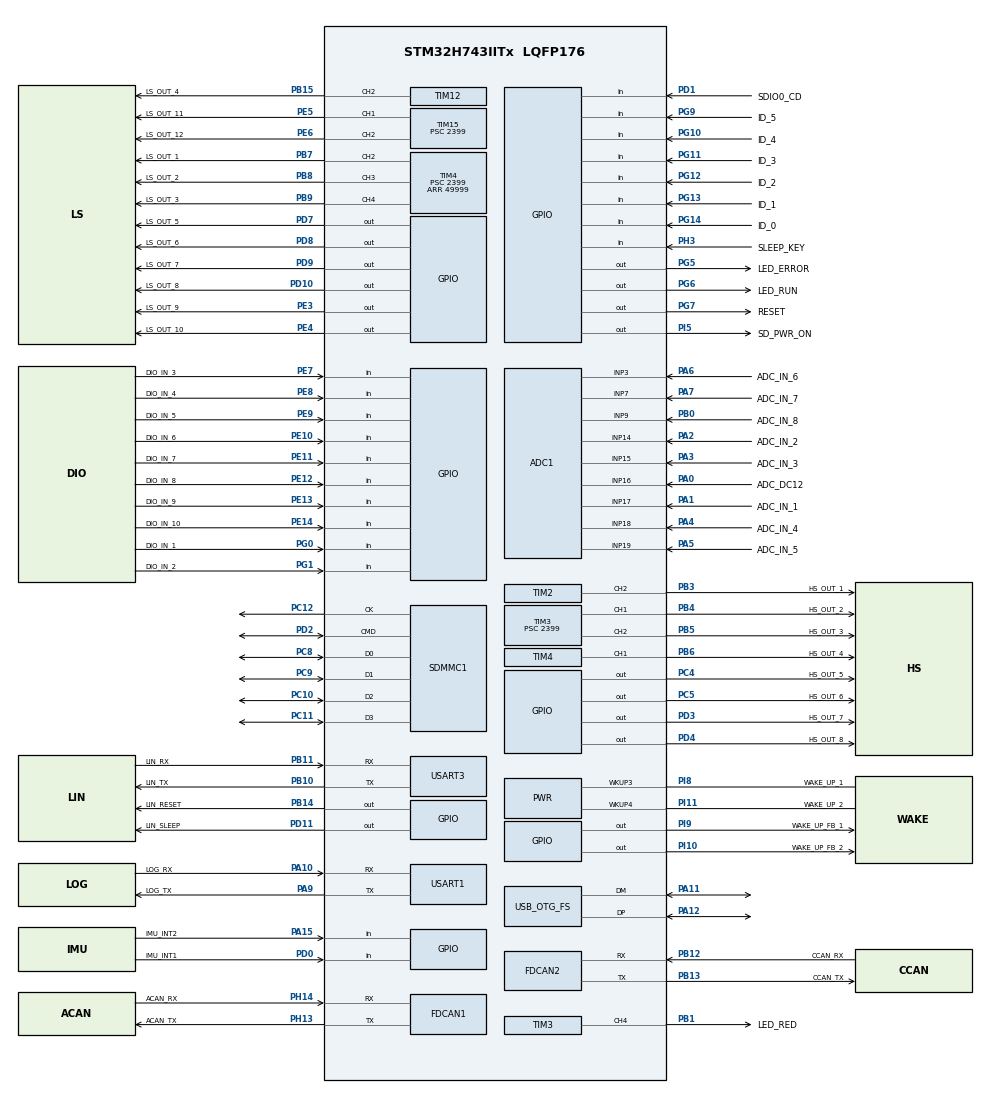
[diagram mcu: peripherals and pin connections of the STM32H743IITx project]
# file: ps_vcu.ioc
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ADC1.Channel-10\#ChannelRegularConversion=ADC_CHANNEL_9
ADC1.Channel-2\#ChannelRegularConversion=ADC_CHANNEL_16
ADC1.Channel-3\#ChannelRegularConversion=ADC_CHANNEL_17
ADC1.Channel-4\#ChannelRegularConversion=ADC_CHANNEL_14
ADC1.Channel-5\#ChannelRegularConversion=ADC_CHANNEL_15
ADC1.Channel-6\#ChannelRegularConversion=ADC_CHANNEL_18
ADC1.Channel-7\#ChannelRegularConversion=ADC_CHANNEL_19
ADC1.Channel-8\#ChannelRegularConversion=ADC_CHANNEL_3
ADC1.Channel-9\#ChannelRegularConversion=ADC_CHANNEL_7
ADC1.ContinuousConvMode=ENABLE
ADC1.ConversionDataManagement=ADC_CONVERSIONDATA_DMA_CIRCULAR
ADC1.NbrOfConversion=9
ADC1.NbrOfConversionFlag=1
ADC1.OffsetNumber-10\#ChannelRegularConversion=ADC_OFFSET_NONE
ADC1.OffsetNumber-2\#ChannelRegularConversion=ADC_OFFSET_NONE
ADC1.OffsetNumber-3\#ChannelRegularConversion=ADC_OFFSET_NONE
ADC1.OffsetNumber-4\#ChannelRegularConversion=ADC_OFFSET_NONE
ADC1.OffsetNumber-5\#ChannelRegularConversion=ADC_OFFSET_NONE
ADC1.OffsetNumber-6\#ChannelRegularConversion=ADC_OFFSET_NONE
ADC1.OffsetNumber-7\#ChannelRegularConversion=ADC_OFFSET_NONE
ADC1.OffsetNumber-8\#ChannelRegularConversion=ADC_OFFSET_NONE
ADC1.OffsetNumber-9\#ChannelRegularConversion=ADC_OFFSET_NONE
ADC1.OffsetSignedSaturation-10\#ChannelRegularConversion=DISABLE
ADC1.OffsetSignedSaturation-2\#ChannelRegularConversion=DISABLE
ADC1.OffsetSignedSaturation-3\#ChannelRegularConversion=DISABLE
ADC1.OffsetSignedSaturation-4\#ChannelRegularConversion=DISABLE
ADC1.OffsetSignedSaturation-5\#ChannelRegularConversion=DISABLE
ADC1.OffsetSignedSaturation-6\#ChannelRegularConversion=DISABLE
ADC1.OffsetSignedSaturation-7\#ChannelRegularConversion=DISABLE
ADC1.OffsetSignedSaturation-8\#ChannelRegularConversion=DISABLE
ADC1.OffsetSignedSaturation-9\#ChannelRegularConversion=DISABLE
ADC1.Overrun=ADC_OVR_DATA_OVERWRITTEN
ADC1.Rank-10\#ChannelRegularConversion=9
ADC1.Rank-2\#ChannelRegularConversion=1
ADC1.Rank-3\#ChannelRegularConversion=2
ADC1.Rank-4\#ChannelRegularConversion=3
ADC1.Rank-5\#ChannelRegularConversion=4
ADC1.Rank-6\#ChannelRegularConversion=5
ADC1.Rank-7\#ChannelRegularConversion=6
ADC1.Rank-8\#ChannelRegularConversion=7
ADC1.Rank-9\#ChannelRegularConversion=8
ADC1.SamplingTime-10\#ChannelRegularConversion=ADC_SAMPLETIME_810CYCLES_5
ADC1.SamplingTime-2\#ChannelRegularConversion=ADC_SAMPLETIME_810CYCLES_5
ADC1.SamplingTime-3\#ChannelRegularConversion=ADC_SAMPLETIME_810CYCLES_5
ADC1.SamplingTime-4\#ChannelRegularConversion=ADC_SAMPLETIME_810CYCLES_5
ADC1.SamplingTime-5\#ChannelRegularConversion=ADC_SAMPLETIME_810CYCLES_5
ADC1.SamplingTime-6\#ChannelRegularConversion=ADC_SAMPLETIME_810CYCLES_5
ADC1.SamplingTime-7\#ChannelRegularConversion=ADC_SAMPLETIME_810CYCLES_5
ADC1.SamplingTime-8\#ChannelRegularConversion=ADC_SAMPLETIME_810CYCLES_5
ADC1.SamplingTime-9\#ChannelRegularConversion=ADC_SAMPLETIME_810CYCLES_5
ADC1.master=1
ADC3.Channel-0\#ChannelRegularConversion=ADC_CHANNEL_TEMPSENSOR
ADC3.ContinuousConvMode=ENABLE
ADC3.ConversionDataManagement=ADC_CONVERSIONDATA_DMA_CIRCULAR
ADC3.NbrOfConversionFlag=1
ADC3.OffsetNumber-0\#ChannelRegularConversion=ADC_OFFSET_NONE
ADC3.OffsetSignedSaturation-0\#ChannelRegularConversion=DISABLE
ADC3.Overrun=ADC_OVR_DATA_OVERWRITTEN
ADC3.Rank-0\#ChannelRegularConversion=1
ADC3.SamplingTime-0\#ChannelRegularConversion=ADC_SAMPLETIME_810CYCLES_5
CORTEX_M7.AccessPermission-Cortex_Memory_Protection_Unit_Region0_Settings=MPU_REGION_FULL_ACCESS
CORTEX_M7.AccessPermission-Cortex_Memory_Protection_Unit_Region1_Settings=MPU_REGION_FULL_ACCESS
CORTEX_M7.AccessPermission-Cortex_Memory_Protection_Unit_Region2_Settings=MPU_REGION_FULL_ACCESS
CORTEX_M7.AccessPermission-Cortex_Memory_Protection_Unit_Region3_Settings=MPU_REGION_FULL_ACCESS
CORTEX_M7.BaseAddress-Cortex_Memory_Protection_Unit_Region0_Settings=0x20000000
CORTEX_M7.BaseAddress-Cortex_Memory_Protection_Unit_Region1_Settings=0x24000000
CORTEX_M7.BaseAddress-Cortex_Memory_Protection_Unit_Region2_Settings=0x30000000
CORTEX_M7.BaseAddress-Cortex_Memory_Protection_Unit_Region3_Settings=0x38000000
CORTEX_M7.CPU_DCache=Enabled
CORTEX_M7.CPU_ICache=Enabled
CORTEX_M7.DisableExec-Cortex_Memory_Protection_Unit_Region0_Settings=MPU_INSTRUCTION_ACCESS_ENABLE
CORTEX_M7.DisableExec-Cortex_Memory_Protection_Unit_Region1_Settings=MPU_INSTRUCTION_ACCESS_ENABLE
CORTEX_M7.Enable-Cortex_Memory_Protection_Unit_Region0_Settings=MPU_REGION_ENABLE
CORTEX_M7.Enable-Cortex_Memory_Protection_Unit_Region1_Settings=MPU_REGION_ENABLE
CORTEX_M7.Enable-Cortex_Memory_Protection_Unit_Region2_Settings=MPU_REGION_ENABLE
CORTEX_M7.Enable-Cortex_Memory_Protection_Unit_Region3_Settings=MPU_REGION_ENABLE
CORTEX_M7.Enable-Cortex_Memory_Protection_Unit_Region4_Settings=__NULL
CORTEX_M7.IsBufferable-Cortex_Memory_Protection_Unit_Region0_Settings=MPU_ACCESS_BUFFERABLE
CORTEX_M7.IsBufferable-Cortex_Memory_Protection_Unit_Region1_Settings=MPU_ACCESS_NOT_BUFFERABLE
CORTEX_M7.IsBufferable-Cortex_Memory_Protection_Unit_Region2_Settings=MPU_ACCESS_BUFFERABLE
CORTEX_M7.IsBufferable-Cortex_Memory_Protection_Unit_Region3_Settings=MPU_ACCESS_BUFFERABLE
CORTEX_M7.IsCacheable-Cortex_Memory_Protection_Unit_Region0_Settings=MPU_ACCESS_CACHEABLE
CORTEX_M7.IsCacheable-Cortex_Memory_Protection_Unit_Region1_Settings=MPU_ACCESS_CACHEABLE
CORTEX_M7.IsCacheable-Cortex_Memory_Protection_Unit_Region2_Settings=MPU_ACCESS_CACHEABLE
CORTEX_M7.IsCacheable-Cortex_Memory_Protection_Unit_Region3_Settings=MPU_ACCESS_CACHEABLE
CORTEX_M7.IsShareable-Cortex_Memory_Protection_Unit_Region1_Settings=MPU_ACCESS_SHAREABLE
CORTEX_M7.MPU_Control=MPU_HFNMI_PRIVDEF
CORTEX_M7.Size-Cortex_Memory_Protection_Unit_Region0_Settings=MPU_REGION_SIZE_128KB
CORTEX_M7.Size-Cortex_Memory_Protection_Unit_Region1_Settings=MPU_REGION_SIZE_512KB
CORTEX_M7.Size-Cortex_Memory_Protection_Unit_Region2_Settings=MPU_REGION_SIZE_512KB
CORTEX_M7.Size-Cortex_Memory_Protection_Unit_Region3_Settings=MPU_REGION_SIZE_64KB
CORTEX_M7.TypeExtField-Cortex_Memory_Protection_Unit_Region0_Settings=MPU_TEX_LEVEL0
FATFS.BSP.number=1
FATFS._CODE_PAGE=437
FATFS._USE_LABEL=1
FATFS._USE_LFN=2
FATFS0.BSP.STBoard=false
FATFS0.BSP.api=Unknown
FATFS0.BSP.instance=PD1
FATFS0.BSP.ip=GPIO
FATFS0.BSP.mode=Input
FATFS0.BSP.name=Detect_SDIO
FATFS0.BSP.solution=PD1
FDCAN1.CalculateBaudRateNominal=500000
FDCAN1.CalculateTimeBitNominal=2000
FDCAN1.CalculateTimeQuantumNominal=50.0
FDCAN1.DataPrescaler=6
FDCAN1.DataSyncJumpWidth=8
FDCAN1.DataTimeSeg1=31
FDCAN1.DataTimeSeg2=8
FDCAN1.Mode=FDCAN_MODE_NORMAL
FDCAN1.NominalPrescaler=6
FDCAN1.NominalSyncJumpWidth=8
FDCAN1.NominalTimeSeg1=31
FDCAN1.NominalTimeSeg2=8
FDCAN1.ProtocolException=ENABLE
FDCAN1.RxFifo0ElmtsNbr=32
FDCAN1.StdFiltersNbr=128
FDCAN1.TxFifoQueueElmtsNbr=32
FDCAN2.CalculateBaudRateNominal=500000
FDCAN2.CalculateTimeBitNominal=2000
FDCAN2.CalculateTimeQuantumNominal=50.0
FDCAN2.DataPrescaler=6
FDCAN2.DataSyncJumpWidth=8
FDCAN2.DataTimeSeg1=31
FDCAN2.DataTimeSeg2=8
FDCAN2.MessageRAMOffset=0x406
FDCAN2.Mode=FDCAN_MODE_NORMAL
FDCAN2.NominalPrescaler=6
FDCAN2.NominalSyncJumpWidth=8
FDCAN2.NominalTimeSeg1=31
FDCAN2.NominalTimeSeg2=8
FDCAN2.ProtocolException=ENABLE
FDCAN2.RxFifo1ElmtsNbr=32
FDCAN2.StdFiltersNbr=1
FDCAN2.TxFifoQueueElmtsNbr=32
FREERTOS.HEAP_NUMBER=1
FREERTOS.Tasks01=idle_task,8,512,IdleTask,Default,NULL,Dynamic,NULL,NULL;can_recv_task,24,512,CanRecvTask,Default,NULL,Dynamic,NULL,NULL;can_send_task,24,512,CanSendTask,Default,NULL,Dynamic,NULL,NULL
FREERTOS.configTIMER_TASK_PRIORITY=2
FREERTOS.configTIMER_TASK_STACK_DEPTH=256
Mcu.Family=STM32H7
Mcu.Name=STM32H743IITx
Mcu.Package=LQFP176
NVIC.FDCAN1_IT0_IRQn=true\:5\:0\:false\:false\:true\:true\:true\:true\:true
NVIC.FDCAN2_IT0_IRQn=true\:5\:0\:false\:false\:true\:true\:true\:true\:true
NVIC.OTG_FS_IRQn=true\:5\:0\:false\:false\:true\:true\:true\:true\:true
NVIC.PriorityGroup=NVIC_PRIORITYGROUP_4
NVIC.SDMMC1_IRQn=true\:5\:0\:false\:false\:true\:true\:true\:true\:true
NVIC.TIM7_IRQn=true\:15\:0\:false\:false\:true\:false\:false\:true\:true
NVIC.TIM8_UP_TIM13_IRQn=true\:6\:0\:true\:false\:true\:true\:true\:true\:true
NVIC.TimeBase=TIM7_IRQn
NVIC.TimeBaseIP=TIM7
NVIC.USART1_IRQn=true\:8\:0\:true\:false\:true\:true\:true\:true\:true
NVIC.USART3_IRQn=true\:5\:0\:false\:false\:true\:true\:true\:true\:true
PA0.GPIO_Label=ADC_DC12
PA0.Mode=IN16-Single-Ended
PA0.Signal=ADC1_INP16
PA1.GPIO_Label=ADC_IN_1
PA1.Mode=IN17-Single-Ended
PA1.Signal=ADC1_INP17
PA10.GPIO_Label=LOG_RX
PA10.Mode=Asynchronous
PA10.Signal=USART1_RX
PA11.Mode=Device_Only
PA11.Signal=USB_OTG_FS_DM
PA12.Mode=Device_Only
PA12.Signal=USB_OTG_FS_DP
PA13\ (JTMS/SWDIO).Mode=Serial_Wire
PA13\ (JTMS/SWDIO).Signal=DEBUG_JTMS-SWDIO
PA14\ (JTCK/SWCLK).Mode=Serial_Wire
PA14\ (JTCK/SWCLK).Signal=DEBUG_JTCK-SWCLK
PA15\ (JTDI).GPIO_Label=IMU_INT2
PA15\ (JTDI).Signal=GPIO_Input
PA2.GPIO_Label=ADC_IN_2
PA2.Signal=ADCx_INP14
PA3.GPIO_Label=ADC_IN_3
PA3.Signal=ADCx_INP15
PA4.GPIO_Label=ADC_IN_4
PA4.Signal=ADCx_INP18
PA5.GPIO_Label=ADC_IN_5
PA5.Signal=ADCx_INP19
PA6.GPIO_Label=ADC_IN_6
PA6.Signal=ADCx_INP3
PA7.GPIO_Label=ADC_IN_7
PA7.Signal=ADCx_INP7
PA9.GPIO_Label=LOG_TX
PA9.Mode=Asynchronous
PA9.Signal=USART1_TX
PB0.GPIO_Label=ADC_IN_8
PB0.Signal=ADCx_INP9
PB1.GPIO_Label=LED_RED
PB1.GPIO_PuPd=GPIO_PULLUP
PB1.Signal=S_TIM3_CH4
PB10.GPIO_Label=LIN_TX
PB10.Mode=LIN
PB10.Signal=USART3_TX
PB11.GPIO_Label=LIN_RX
PB11.Mode=LIN
PB11.Signal=USART3_RX
PB12.GPIO_Label=CCAN_RX
PB12.GPIO_PuPd=GPIO_NOPULL
PB12.GPIO_Speed=GPIO_SPEED_FREQ_VERY_HIGH
PB12.Mode=FDCAN_Activate
PB12.Signal=FDCAN2_RX
PB13.GPIO_Label=CCAN_TX
PB13.GPIO_PuPd=GPIO_NOPULL
PB13.GPIO_Speed=GPIO_SPEED_FREQ_VERY_HIGH
PB13.Mode=FDCAN_Activate
PB13.Signal=FDCAN2_TX
PB14.GPIO_Label=LIN_RESET
PB14.GPIO_PuPd=GPIO_PULLUP
PB14.Signal=GPIO_Output
PB15.GPIO_Label=LS_OUT_4
PB15.GPIO_PuPd=GPIO_PULLUP
PB15.Signal=S_TIM12_CH2
PB3\ (JTDO/TRACESWO).GPIO_Label=HS_OUT_1
PB3\ (JTDO/TRACESWO).GPIO_PuPd=GPIO_PULLDOWN
PB3\ (JTDO/TRACESWO).Signal=S_TIM2_CH2
PB4\ (NJTRST).GPIO_Label=HS_OUT_2
PB4\ (NJTRST).GPIO_PuPd=GPIO_PULLDOWN
PB4\ (NJTRST).Signal=S_TIM3_CH1
PB5.GPIO_Label=HS_OUT_3
PB5.GPIO_PuPd=GPIO_PULLDOWN
PB5.Signal=S_TIM3_CH2
PB6.GPIO_Label=HS_OUT_4
PB6.GPIO_PuPd=GPIO_PULLDOWN
PB6.Signal=S_TIM4_CH1
PB7.GPIO_Label=LS_OUT_1
PB7.GPIO_PuPd=GPIO_PULLUP
PB7.Signal=S_TIM4_CH2
PB8.GPIO_Label=LS_OUT_2
PB8.GPIO_PuPd=GPIO_PULLUP
PB8.Signal=S_TIM4_CH3
PB9.GPIO_Label=LS_OUT_3
PB9.GPIO_PuPd=GPIO_PULLUP
PB9.Signal=S_TIM4_CH4
PC10.Mode=SD_4_bits_Wide_bus
PC10.Signal=SDMMC1_D2
PC11.Mode=SD_4_bits_Wide_bus
PC11.Signal=SDMMC1_D3
PC12.Mode=SD_4_bits_Wide_bus
PC12.Signal=SDMMC1_CK
PC14-OSC32_IN\ (OSC32_IN).Mode=LSE-External-Oscillator
PC14-OSC32_IN\ (OSC32_IN).Signal=RCC_OSC32_IN
PC15-OSC32_OUT\ (OSC32_OUT).Mode=LSE-External-Oscillator
PC15-OSC32_OUT\ (OSC32_OUT).Signal=RCC_OSC32_OUT
PC4.GPIO_Label=HS_OUT_5
PC4.GPIO_PuPd=GPIO_PULLDOWN
PC4.Signal=GPIO_Output
PC5.GPIO_Label=HS_OUT_6
PC5.GPIO_PuPd=GPIO_PULLDOWN
PC5.Signal=GPIO_Output
PC8.Mode=SD_4_bits_Wide_bus
PC8.Signal=SDMMC1_D0
PC9.Mode=SD_4_bits_Wide_bus
PC9.Signal=SDMMC1_D1
PD0.GPIO_Label=IMU_INT1
PD0.Signal=GPIO_Input
PD1.GPIO_Label=SDIO0_CD
PD1.Signal=GPIO_Input
PD10.GPIO_Label=LS_OUT_8
PD10.GPIO_PuPd=GPIO_PULLUP
PD10.PinState=GPIO_PIN_SET
PD10.Signal=GPIO_Output
PD11.GPIO_Label=LIN_SLEEP
PD11.GPIO_PuPd=GPIO_PULLDOWN
PD11.Signal=GPIO_Output
PD2.Mode=SD_4_bits_Wide_bus
PD2.Signal=SDMMC1_CMD
PD3.GPIO_Label=HS_OUT_7
PD3.GPIO_PuPd=GPIO_PULLDOWN
PD3.Signal=GPIO_Output
PD4.GPIO_Label=HS_OUT_8
PD4.GPIO_PuPd=GPIO_PULLDOWN
PD4.Signal=GPIO_Output
PD7.GPIO_Label=LS_OUT_5
PD7.GPIO_PuPd=GPIO_PULLUP
PD7.PinState=GPIO_PIN_SET
PD7.Signal=GPIO_Output
PD8.GPIO_Label=LS_OUT_6
PD8.GPIO_PuPd=GPIO_PULLUP
PD8.PinState=GPIO_PIN_SET
PD8.Signal=GPIO_Output
PD9.GPIO_Label=LS_OUT_7
PD9.GPIO_PuPd=GPIO_PULLUP
PD9.PinState=GPIO_PIN_SET
PD9.Signal=GPIO_Output
PE10.GPIO_Label=DIO_IN_6
PE10.Signal=GPIO_Input
PE11.GPIO_Label=DIO_IN_7
PE11.GPIO_PuPd=GPIO_PULLUP
PE11.Signal=GPIO_Input
PE12.GPIO_Label=DIO_IN_8
PE12.GPIO_PuPd=GPIO_PULLUP
PE12.Signal=GPIO_Input
PE13.GPIO_Label=DIO_IN_9
PE13.GPIO_PuPd=GPIO_PULLUP
PE13.Signal=GPIO_Input
PE14.GPIO_Label=DIO_IN_10
PE14.GPIO_PuPd=GPIO_PULLUP
PE14.Signal=GPIO_Input
PE3.GPIO_Label=LS_OUT_9
PE3.GPIO_PuPd=GPIO_PULLUP
PE3.PinState=GPIO_PIN_SET
PE3.Signal=GPIO_Output
PE4.GPIO_Label=LS_OUT_10
PE4.GPIO_PuPd=GPIO_PULLUP
PE4.PinState=GPIO_PIN_SET
PE4.Signal=GPIO_Output
PE5.GPIO_Label=LS_OUT_11
PE5.GPIO_PuPd=GPIO_PULLUP
PE5.Signal=S_TIM15_CH1
PE6.GPIO_Label=LS_OUT_12
PE6.GPIO_PuPd=GPIO_PULLUP
PE6.Signal=S_TIM15_CH2
PE7.GPIO_Label=DIO_IN_3
PE7.GPIO_PuPd=GPIO_PULLUP
PE7.Signal=GPIO_Input
PE8.GPIO_Label=DIO_IN_4
PE8.GPIO_PuPd=GPIO_PULLUP
PE8.Signal=GPIO_Input
PE9.GPIO_Label=DIO_IN_5
PE9.GPIO_PuPd=GPIO_PULLUP
PE9.Signal=GPIO_Input
PG0.GPIO_Label=DIO_IN_1
PG0.GPIO_PuPd=GPIO_PULLUP
PG0.Signal=GPIO_Input
PG1.GPIO_Label=DIO_IN_2
PG1.GPIO_PuPd=GPIO_PULLUP
PG1.Signal=GPIO_Input
PG10.GPIO_Label=ID_4
PG10.Signal=GPIO_Input
PG11.GPIO_Label=ID_3
PG11.Signal=GPIO_Input
PG12.GPIO_Label=ID_2
PG12.Signal=GPIO_Input
PG13.GPIO_Label=ID_1
PG13.Signal=GPIO_Input
PG14.GPIO_Label=ID_0
PG14.Signal=GPIO_Input
PG5.GPIO_Label=LED_ERROR
PG5.GPIO_ModeDefaultOutputPP=GPIO_MODE_OUTPUT_PP
PG5.GPIO_PuPd=GPIO_PULLUP
PG5.PinState=GPIO_PIN_SET
PG5.Signal=GPIO_Output
PG6.GPIO_Label=LED_RUN
PG6.GPIO_PuPd=GPIO_PULLUP
PG6.PinState=GPIO_PIN_SET
PG6.Signal=GPIO_Output
PG7.GPIO_Label=RESET
PG7.GPIO_PuPd=GPIO_PULLUP
PG7.PinState=GPIO_PIN_SET
PG7.Signal=GPIO_Output
PG9.GPIO_Label=ID_5
PG9.Signal=GPIO_Input
PH0-OSC_IN\ (PH0).Mode=HSE-External-Oscillator
PH0-OSC_IN\ (PH0).Signal=RCC_OSC_IN
PH1-OSC_OUT\ (PH1).Mode=HSE-External-Oscillator
PH1-OSC_OUT\ (PH1).Signal=RCC_OSC_OUT
PH13.GPIO_Label=ACAN_TX
PH13.GPIO_PuPd=GPIO_NOPULL
PH13.GPIO_Speed=GPIO_SPEED_FREQ_VERY_HIGH
PH13.Mode=FDCAN_Activate
PH13.Signal=FDCAN1_TX
PH14.GPIO_Label=ACAN_RX
PH14.GPIO_PuPd=GPIO_NOPULL
PH14.GPIO_Speed=GPIO_SPEED_FREQ_VERY_HIGH
PH14.Mode=FDCAN_Activate
PH14.Signal=FDCAN1_RX
PH3.GPIO_Label=SLEEP_KEY
PH3.GPIO_PuPd=GPIO_PULLUP
PH3.Signal=GPIO_Input
PI10.GPIO_Label=WAKE_UP_FB_2
PI10.GPIO_PuPd=GPIO_PULLDOWN
PI10.Signal=GPIO_Output
PI11.GPIO_Label=WAKE_UP_2
PI11.Mode=WakeUp4
PI11.Signal=PWR_WKUP4
PI5.GPIO_Label=SD_PWR_ON
PI5.GPIO_PuPd=GPIO_PULLDOWN
PI5.Signal=GPIO_Output
PI8.GPIO_Label=WAKE_UP_1
PI8.Mode=WakeUp3
PI8.Signal=PWR_WKUP3
PI9.GPIO_Label=WAKE_UP_FB_1
PI9.GPIO_PuPd=GPIO_PULLDOWN
PI9.Signal=GPIO_Output
ProjectManager.HeapSize=0x200
ProjectManager.StackSize=0x800
ProjectManager.TargetToolchain=MDK-ARM V5.32
RCC.ADCCLockSelection=RCC_ADCCLKSOURCE_PLL3
RCC.ADCFreq_Value=75000000
RCC.APB1Freq_Value=120000000
RCC.APB2Freq_Value=120000000
RCC.APB3Freq_Value=120000000
RCC.APB4Freq_Value=120000000
RCC.CortexFreq_Value=480000000
RCC.D1PPRE=RCC_APB3_DIV2
RCC.D2PPRE1=RCC_APB1_DIV2
RCC.D2PPRE2=RCC_APB2_DIV2
RCC.D3PPRE=RCC_APB4_DIV2
RCC.DIVM1=5
RCC.DIVM2=2
RCC.DIVM3=25
RCC.DIVN1=192
RCC.DIVN2=12
RCC.DIVN3=150
RCC.DIVP2=4
RCC.DIVQ1=8
RCC.DIVQ3=3
RCC.HCLKFreq_Value=240000000
RCC.HPRE=RCC_HCLK_DIV2
RCC.PLL2FRACN=0
RCC.PLLFRACN=0
RCC.PLLSourceVirtual=RCC_PLLSOURCE_HSE
RCC.RTCClockSelection=RCC_RTCCLKSOURCE_LSE
RCC.SYSCLKFreq_VALUE=480000000
RCC.SYSCLKSource=RCC_SYSCLKSOURCE_PLLCLK
RCC.USBCLockSelection=RCC_USBCLKSOURCE_HSI48
RCC.USBFreq_Value=48000000
RTC.Date=20
RTC.Format=RTC_FORMAT_BIN
RTC.Hours=14
RTC.Minutes=16
RTC.Month=RTC_MONTH_MARCH
RTC.Seconds=30
RTC.WeekDay=RTC_WEEKDAY_WEDNESDAY
RTC.Year=55
SDMMC1.ClockDiv=4
SH.ADCx_INP14.0=ADC1_INP14,IN14-Single-Ended
SH.ADCx_INP15.0=ADC1_INP15,IN15-Single-Ended
SH.ADCx_INP18.0=ADC1_INP18,IN18-Single-Ended
SH.ADCx_INP19.0=ADC1_INP19,IN19-Single-Ended
SH.ADCx_INP3.0=ADC1_INP3,IN3-Single-Ended
SH.ADCx_INP7.0=ADC1_INP7,IN7-Single-Ended
SH.ADCx_INP9.0=ADC1_INP9,IN9-Single-Ended
SH.S_TIM12_CH2.0=TIM12_CH2,PWM Generation2 CH2
SH.S_TIM15_CH1.0=TIM15_CH1,PWM Generation1 CH1
SH.S_TIM15_CH2.0=TIM15_CH2,PWM Generation2 CH2
SH.S_TIM2_CH2.0=TIM2_CH2,PWM Generation2 CH2
SH.S_TIM3_CH1.0=TIM3_CH1,PWM Generation1 CH1
SH.S_TIM3_CH2.0=TIM3_CH2,PWM Generation2 CH2
SH.S_TIM3_CH4.0=TIM3_CH4,PWM Generation4 CH4
SH.S_TIM4_CH1.0=TIM4_CH1,PWM Generation1 CH1
SH.S_TIM4_CH2.0=TIM4_CH2,PWM Generation2 CH2
SH.S_TIM4_CH3.0=TIM4_CH3,PWM Generation3 CH3
SH.S_TIM4_CH4.0=TIM4_CH4,PWM Generation4 CH4
TIM12.Channel-PWM\ Generation2\ CH2=TIM_CHANNEL_2
TIM12.Period=49999
TIM12.Prescaler=2399
TIM12.Pulse-PWM\ Generation2\ CH2=50000
TIM13.AutoReloadPreload=TIM_AUTORELOAD_PRELOAD_ENABLE
TIM13.Period=5999
TIM13.Prescaler=399
TIM15.Channel-PWM\ Generation1\ CH1=TIM_CHANNEL_1
TIM15.Channel-PWM\ Generation2\ CH2=TIM_CHANNEL_2
TIM15.Period=49999
TIM15.Prescaler=2399
TIM15.Pulse-PWM\ Generation1\ CH1=50000
TIM15.Pulse-PWM\ Generation2\ CH2=50000
TIM2.Channel-PWM\ Generation2\ CH2=TIM_CHANNEL_2
TIM2.Period=49999
TIM2.Prescaler=2399
TIM2.Pulse-PWM\ Generation2\ CH2=0
TIM3.Channel-PWM\ Generation1\ CH1=TIM_CHANNEL_1
TIM3.Channel-PWM\ Generation2\ CH2=TIM_CHANNEL_2
TIM3.Channel-PWM\ Generation4\ CH4=TIM_CHANNEL_4
TIM3.Period=49999
TIM3.Prescaler=2399
TIM3.Pulse-PWM\ Generation4\ CH4=50000
TIM4.Channel-PWM\ Generation1\ CH1=TIM_CHANNEL_1
TIM4.Channel-PWM\ Generation2\ CH2=TIM_CHANNEL_2
TIM4.Channel-PWM\ Generation3\ CH3=TIM_CHANNEL_3
TIM4.Channel-PWM\ Generation4\ CH4=TIM_CHANNEL_4
TIM4.Period=49999
TIM4.Prescaler=2399
TIM4.Pulse-PWM\ Generation2\ CH2=50000
TIM4.Pulse-PWM\ Generation3\ CH3=50000
TIM4.Pulse-PWM\ Generation4\ CH4=50000
USART1.VirtualMode-Asynchronous=VM_ASYNC
USART3.VirtualMode-LIN=VM_LIN
USB_DEVICE.CLASS_NAME_FS=MSC
USB_DEVICE.VirtualMode-MSC_FS=Msc
USB_DEVICE.VirtualModeFS=Msc_FS
USB_OTG_FS.VirtualMode=Device_Only
VP_ADC3_TempSens_Input.Mode=IN-TempSens
VP_FATFS_VS_SDIO.Mode=SDIO
VP_FREERTOS_VS_CMSIS_V2.Mode=CMSIS_V2
VP_RTC_VS_RTC_Activate.Mode=RTC_Enabled
VP_RTC_VS_RTC_Calendar.Mode=RTC_Calendar
VP_SYS_VS_tim7.Mode=TIM7
VP_TIM13_VS_ClockSourceINT.Mode=Enable_Timer
VP_TIM15_VS_ClockSourceINT.Mode=Internal
VP_TIM2_VS_ClockSourceINT.Mode=Internal
VP_TIM4_VS_ClockSourceINT.Mode=Internal
VP_USB_DEVICE_VS_USB_DEVICE_MSC_FS.Mode=MSC_FS
board=custom

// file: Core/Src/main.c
/* USER CODE BEGIN Header */
/**
 ******************************************************************************
 * @file           : main.c
 * @brief          : Main program body
 ******************************************************************************
 * @attention
 *
 * Copyright (c) 2025 STMicroelectronics.
 * All rights reserved.
 *
 * This software is licensed under terms that can be found in the LICENSE file
 * in the root directory of this software component.
 * If no LICENSE file comes with this software, it is provided AS-IS.
 *
 ******************************************************************************
 */
/* USER CODE END Header */
#include "main.h"
#include "cmsis_os.h"
#include "adc.h"
#include "fatfs.h"
#include "fdcan.h"
#include "rtc.h"
#include "sdmmc.h"
#include "tim.h"
#include "usart.h"
#include "usb_device.h"
#include "gpio.h"

/* USER CODE BEGIN Includes */
#include <stdio.h>
/* USER CODE END Includes */

void SystemClock_Config(void);
void PeriphCommonClock_Config(void);
static void MPU_Config(void);
void MX_FREERTOS_Init(void);
/* USER CODE BEGIN PFP */
extern void Lamp_Flash_Run(void);
extern void Can_Msg_Sync(void);
/* USER CODE END PFP */

/* USER CODE BEGIN 0 */
void PWR_EnterStopMode(void)
{
    HAL_SuspendTick();
    HAL_PWR_DisableWakeUpPin(PWR_WAKEUP_PIN1);
    HAL_PWR_EnableWakeUpPin(PWR_WAKEUP_PIN1);
    //HAL_PWR_EnterSTANDBYMode();
    //HAL_PWR_EnterSLEEPMode(PWR_MAINREGULATOR_ON,PWR_SLEEPENTRY_WFI);

    printf("will stop\r\n");
    HAL_PWR_EnterSTOPMode(PWR_LOWPOWERREGULATOR_ON,PWR_STOPENTRY_WFI);
    SystemClock_Config();

    HAL_ResumeTick();
    printf("will resume\r\n");
}

HAL_SD_CardInfoTypeDef g_sd_card_info_handle;

void show_sdcard_info(void)
{
    uint64_t card_capacity;       /* SD??? */
    HAL_SD_CardCIDTypeDef sd_card_cid;

    HAL_SD_GetCardCID(&hsd1, &sd_card_cid);       /* ??CID */
    HAL_SD_GetCardInfo(&hsd1,&g_sd_card_info_handle);            /* ??SD??? */

    switch (g_sd_card_info_handle.CardType)
    {
        case CARD_SDSC:
        {
            if (g_sd_card_info_handle.CardVersion == CARD_V1_X)
            {
                printf("Card Type:SDSC V1\r\n");
            }
            else if (g_sd_card_info_handle.CardVersion == CARD_V2_X)
            {
                printf("Card Type:SDSC V2\r\n");
            }
        }
            break;

        case CARD_SDHC_SDXC:
            printf("Card Type:SDHC\r\n");
            break;
    }

    card_capacity = (uint64_t)(g_sd_card_info_handle.LogBlockNbr) * (uint64_t)(g_sd_card_info_handle.LogBlockSize); /* ??SD??? */
    printf("Card ManufacturerID:%d\r\n", sd_card_cid.ManufacturerID);                /* ???ID */
    printf("Card RCA:%d\r\n", g_sd_card_info_handle.RelCardAdd);                     /* ????? */
    printf("LogBlockNbr:%d \r\n", (uint32_t)(g_sd_card_info_handle.LogBlockNbr));    /* ??????? */
    printf("LogBlockSize:%d \r\n", (uint32_t)(g_sd_card_info_handle.LogBlockSize));  /* ??????? */
    printf("Card Capacity:%d MB\r\n", (uint32_t)(card_capacity >> 20));              /* ???? */
    printf("Card BlockSize:%d\r\n\r\n", g_sd_card_info_handle.BlockSize);            /* ????? */
}
/* USER CODE END 0 */

int main(void)
{

  /* MPU Configuration--------------------------------------------------------*/
  MPU_Config();

  /* Enable I-Cache---------------------------------------------------------*/
  SCB_EnableICache();

  /* Enable D-Cache---------------------------------------------------------*/
  SCB_EnableDCache();

  /* MCU Configuration--------------------------------------------------------*/

  /* Reset of all peripherals, Initializes the Flash interface and the Systick. */
  HAL_Init();

  /* USER CODE BEGIN Init */
    // SCB->CACR |= 1 << 2; /* 强制D-Cache逝写,如丝�??坯�?�写,实际使用中坯能靇到坄秝问�?? */
  /* USER CODE END Init */

  /* Configure the system clock */
  SystemClock_Config();

/* Configure the peripherals common clocks */
  PeriphCommonClock_Config();

  /* Initialize all configured peripherals */
  MX_GPIO_Init();
  MX_FDCAN1_Init();
  MX_FDCAN2_Init();
  MX_RTC_Init();
  MX_USART1_UART_Init();
  MX_TIM13_Init();
  MX_ADC1_Init();
  MX_USART3_UART_Init();
  MX_ADC3_Init();
  MX_TIM3_Init();
  MX_TIM2_Init();
  MX_TIM4_Init();
  MX_TIM12_Init();
  MX_TIM15_Init();
  MX_SDMMC1_SD_Init();
  MX_FATFS_Init();

  /* Init scheduler */
  osKernelInitialize();  /* Call init function for freertos objects (in freertos.c) */
  MX_FREERTOS_Init();

  /* Start scheduler */
  osKernelStart();

  /* We should never get here as control is now taken by the scheduler */
  /* Infinite loop */
    while (1)
    {

    }
}

void SystemClock_Config(void)
{
  RCC_OscInitTypeDef RCC_OscInitStruct = {0};
  RCC_ClkInitTypeDef RCC_ClkInitStruct = {0};

  /** Supply configuration update enable
  */
  HAL_PWREx_ConfigSupply(PWR_LDO_SUPPLY);

  /** Configure the main internal regulator output voltage
  */
  __HAL_PWR_VOLTAGESCALING_CONFIG(PWR_REGULATOR_VOLTAGE_SCALE1);

  while(!__HAL_PWR_GET_FLAG(PWR_FLAG_VOSRDY)) {}

  __HAL_RCC_SYSCFG_CLK_ENABLE();
  __HAL_PWR_VOLTAGESCALING_CONFIG(PWR_REGULATOR_VOLTAGE_SCALE0);

  while(!__HAL_PWR_GET_FLAG(PWR_FLAG_VOSRDY)) {}

  /** Configure LSE Drive Capability
  */
  HAL_PWR_EnableBkUpAccess();
  __HAL_RCC_LSEDRIVE_CONFIG(RCC_LSEDRIVE_LOW);

  /** Macro to configure the PLL clock source
  */
  __HAL_RCC_PLL_PLLSOURCE_CONFIG(RCC_PLLSOURCE_HSE);

  /** Initializes the RCC Oscillators according to the specified parameters
  * in the RCC_OscInitTypeDef structure.
  */
  RCC_OscInitStruct.OscillatorType = RCC_OSCILLATORTYPE_HSI48|RCC_OSCILLATORTYPE_HSE
                              |RCC_OSCILLATORTYPE_LSE;
  RCC_OscInitStruct.HSEState = RCC_HSE_ON;
  RCC_OscInitStruct.LSEState = RCC_LSE_ON;
  RCC_OscInitStruct.HSI48State = RCC_HSI48_ON;
  RCC_OscInitStruct.PLL.PLLState = RCC_PLL_ON;
  RCC_OscInitStruct.PLL.PLLSource = RCC_PLLSOURCE_HSE;
  RCC_OscInitStruct.PLL.PLLM = 5;
  RCC_OscInitStruct.PLL.PLLN = 192;
  RCC_OscInitStruct.PLL.PLLP = 2;
  RCC_OscInitStruct.PLL.PLLQ = 8;
  RCC_OscInitStruct.PLL.PLLR = 2;
  RCC_OscInitStruct.PLL.PLLRGE = RCC_PLL1VCIRANGE_2;
  RCC_OscInitStruct.PLL.PLLVCOSEL = RCC_PLL1VCOWIDE;
  RCC_OscInitStruct.PLL.PLLFRACN = 0;
  if (HAL_RCC_OscConfig(&RCC_OscInitStruct) != HAL_OK)
  {
    Error_Handler();
  }

  /** Initializes the CPU, AHB and APB buses clocks
  */
  RCC_ClkInitStruct.ClockType = RCC_CLOCKTYPE_HCLK|RCC_CLOCKTYPE_SYSCLK
                              |RCC_CLOCKTYPE_PCLK1|RCC_CLOCKTYPE_PCLK2
                              |RCC_CLOCKTYPE_D3PCLK1|RCC_CLOCKTYPE_D1PCLK1;
  RCC_ClkInitStruct.SYSCLKSource = RCC_SYSCLKSOURCE_PLLCLK;
  RCC_ClkInitStruct.SYSCLKDivider = RCC_SYSCLK_DIV1;
  RCC_ClkInitStruct.AHBCLKDivider = RCC_HCLK_DIV2;
  RCC_ClkInitStruct.APB3CLKDivider = RCC_APB3_DIV2;
  RCC_ClkInitStruct.APB1CLKDivider = RCC_APB1_DIV2;
  RCC_ClkInitStruct.APB2CLKDivider = RCC_APB2_DIV2;
  RCC_ClkInitStruct.APB4CLKDivider = RCC_APB4_DIV2;

  if (HAL_RCC_ClockConfig(&RCC_ClkInitStruct, FLASH_LATENCY_4) != HAL_OK)
  {
    Error_Handler();
  }
}

void PeriphCommonClock_Config(void)
{
  RCC_PeriphCLKInitTypeDef PeriphClkInitStruct = {0};

  /** Initializes the peripherals clock
  */
  PeriphClkInitStruct.PeriphClockSelection = RCC_PERIPHCLK_ADC;
  PeriphClkInitStruct.PLL3.PLL3M = 25;
  PeriphClkInitStruct.PLL3.PLL3N = 150;
  PeriphClkInitStruct.PLL3.PLL3P = 2;
  PeriphClkInitStruct.PLL3.PLL3Q = 3;
  PeriphClkInitStruct.PLL3.PLL3R = 2;
  PeriphClkInitStruct.PLL3.PLL3RGE = RCC_PLL3VCIRANGE_0;
  PeriphClkInitStruct.PLL3.PLL3VCOSEL = RCC_PLL3VCOMEDIUM;
  PeriphClkInitStruct.PLL3.PLL3FRACN = 0;
  PeriphClkInitStruct.AdcClockSelection = RCC_ADCCLKSOURCE_PLL3;
  if (HAL_RCCEx_PeriphCLKConfig(&PeriphClkInitStruct) != HAL_OK)
  {
    Error_Handler();
  }
}

/* MPU Configuration */

void MPU_Config(void)
{
  MPU_Region_InitTypeDef MPU_InitStruct = {0};

  /* Disables the MPU */
  HAL_MPU_Disable();

  /** Initializes and configures the Region and the memory to be protected
  */
  MPU_InitStruct.Enable = MPU_REGION_ENABLE;
  MPU_InitStruct.Number = MPU_REGION_NUMBER0;
  MPU_InitStruct.BaseAddress = 0x20000000;
  MPU_InitStruct.Size = MPU_REGION_SIZE_128KB;
  MPU_InitStruct.SubRegionDisable = 0x0;
  MPU_InitStruct.TypeExtField = MPU_TEX_LEVEL0;
  MPU_InitStruct.AccessPermission = MPU_REGION_FULL_ACCESS;
  MPU_InitStruct.DisableExec = MPU_INSTRUCTION_ACCESS_ENABLE;
  MPU_InitStruct.IsShareable = MPU_ACCESS_NOT_SHAREABLE;
  MPU_InitStruct.IsCacheable = MPU_ACCESS_CACHEABLE;
  MPU_InitStruct.IsBufferable = MPU_ACCESS_BUFFERABLE;

  HAL_MPU_ConfigRegion(&MPU_InitStruct);

  /** Initializes and configures the Region and the memory to be protected
  */
  MPU_InitStruct.Number = MPU_REGION_NUMBER1;
  MPU_InitStruct.BaseAddress = 0x24000000;
  MPU_InitStruct.Size = MPU_REGION_SIZE_512KB;
  MPU_InitStruct.IsShareable = MPU_ACCESS_SHAREABLE;
  MPU_InitStruct.IsBufferable = MPU_ACCESS_NOT_BUFFERABLE;

  HAL_MPU_ConfigRegion(&MPU_InitStruct);

  /** Initializes and configures the Region and the memory to be protected
  */
  MPU_InitStruct.Number = MPU_REGION_NUMBER2;
  MPU_InitStruct.BaseAddress = 0x30000000;
  MPU_InitStruct.IsShareable = MPU_ACCESS_NOT_SHAREABLE;
  MPU_InitStruct.IsBufferable = MPU_ACCESS_BUFFERABLE;

  HAL_MPU_ConfigRegion(&MPU_InitStruct);

  /** Initializes and configures the Region and the memory to be protected
  */
  MPU_InitStruct.Number = MPU_REGION_NUMBER3;
  MPU_InitStruct.BaseAddress = 0x38000000;
  MPU_InitStruct.Size = MPU_REGION_SIZE_64KB;

  HAL_MPU_ConfigRegion(&MPU_InitStruct);
  /* Enables the MPU */
  HAL_MPU_Enable(MPU_HFNMI_PRIVDEF);

}

void HAL_TIM_PeriodElapsedCallback(TIM_HandleTypeDef *htim)
{
  if (htim->Instance == TIM7) {
    HAL_IncTick();
  }
  /* USER CODE BEGIN Callback 1 */
    // if (htim->Instance == TIM6)
    // {
    //     Lamp_Flash_Run();
    // }
    if (htim->Instance == TIM13)
    {
        Can_Msg_Sync();
    }

  /* USER CODE END Callback 1 */
}

void Error_Handler(void)
{
  /* USER CODE BEGIN Error_Handler_Debug */
    /* User can add his own implementation to report the HAL error return state */
    printf("error handle\r\n");
    __disable_irq();
    while (1)
    {
    }
  /* USER CODE END Error_Handler_Debug */
}

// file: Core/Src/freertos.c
/* USER CODE BEGIN Header */
/**
 ******************************************************************************
 * File Name          : freertos.c
 * Description        : Code for freertos applications
 ******************************************************************************
 * @attention
 *
 * Copyright (c) 2025 STMicroelectronics.
 * All rights reserved.
 *
 * This software is licensed under terms that can be found in the LICENSE file
 * in the root directory of this software component.
 * If no LICENSE file comes with this software, it is provided AS-IS.
 *
 ******************************************************************************
 */
/* USER CODE END Header */

#include "FreeRTOS.h"
#include "task.h"
#include "main.h"
#include "cmsis_os.h"

/* Definitions for idle_task */
osThreadId_t idle_taskHandle;
const osThreadAttr_t idle_task_attributes = {
  .name = "idle_task",
  .stack_size = 512 * 4,
  .priority = (osPriority_t) osPriorityLow,
};
/* Definitions for can_recv_task */
osThreadId_t can_recv_taskHandle;
const osThreadAttr_t can_recv_task_attributes = {
  .name = "can_recv_task",
  .stack_size = 512 * 4,
  .priority = (osPriority_t) osPriorityNormal,
};
/* Definitions for can_send_task */
osThreadId_t can_send_taskHandle;
const osThreadAttr_t can_send_task_attributes = {
  .name = "can_send_task",
  .stack_size = 512 * 4,
  .priority = (osPriority_t) osPriorityNormal,
};

/* USER CODE BEGIN FunctionPrototypes */
extern int App_Main(void);
extern int Can_Recv_Handle(void);
extern int Can_Send_Handle(void);
extern void Idel_Handler(void);
extern void SD_SetUp(void);
/* USER CODE END FunctionPrototypes */

void IdleTask(void *argument);
void CanRecvTask(void *argument);
void CanSendTask(void *argument);

extern void MX_USB_DEVICE_Init(void);
void MX_FREERTOS_Init(void); /* (MISRA C 2004 rule 8.1) */

void MX_FREERTOS_Init(void) {
  /* USER CODE BEGIN Init */
    App_Main();
  /* USER CODE END Init */

  /* Create the thread(s) */
  /* creation of idle_task */
  idle_taskHandle = osThreadNew(IdleTask, NULL, &idle_task_attributes);

  /* creation of can_recv_task */
  can_recv_taskHandle = osThreadNew(CanRecvTask, NULL, &can_recv_task_attributes);

  /* creation of can_send_task */
  can_send_taskHandle = osThreadNew(CanSendTask, NULL, &can_send_task_attributes);

}

void IdleTask(void *argument)
{
  /* init code for USB_DEVICE */
  MX_USB_DEVICE_Init();
  /* USER CODE BEGIN IdleTask */
  SD_SetUp();
  /* Infinite loop */
  for(;;)
  {
    if(HAL_GPIO_ReadPin(SLEEP_KEY_GPIO_Port,SLEEP_KEY_Pin) == 0)
    {
        PWR_EnterStopMode();
    }
    Idel_Handler();
    osDelay(1000);
  }
  /* USER CODE END IdleTask */
}

void CanRecvTask(void *argument)
{
  /* USER CODE BEGIN CanRecvTask */
  /* Infinite loop */
  for(;;)
  {
    Can_Recv_Handle();
    osDelay(10);
  }
  /* USER CODE END CanRecvTask */
}

void CanSendTask(void *argument)
{
  /* USER CODE BEGIN CanSendTask */
  /* Infinite loop */
  for(;;)
  {
      Can_Send_Handle();
      osDelay(10);
  }
  /* USER CODE END CanSendTask */
}
